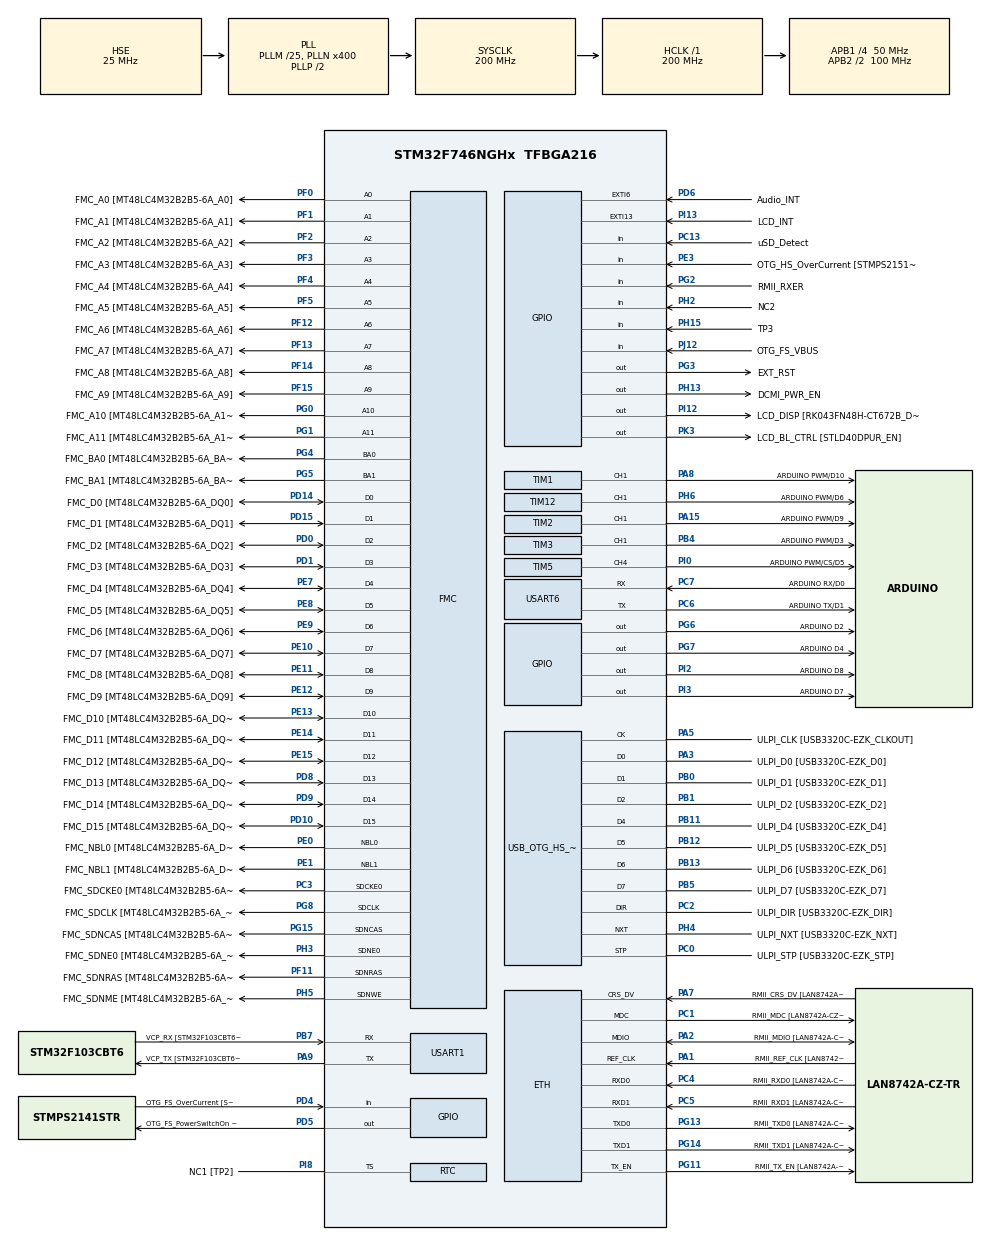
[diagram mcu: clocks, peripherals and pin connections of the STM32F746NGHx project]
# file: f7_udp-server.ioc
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VP_TIM5_VS_ClockSourceINT.Mode=Internal
PD12.GPIO_Label=QSPI_D1 [N25Q128A13EF840E_DQ1]
FMC.SDClockPeriod2=FMC_SDRAM_CLOCK_PERIOD_2
FMC.SDClockPeriod1=FMC_SDRAM_CLOCK_PERIOD_2
SH.FMC_A0.0=FMC_A0,12b-sda1
PH15.GPIO_Label=TP3
NVIC.TIM6_DAC_IRQn=true\:0\:0\:false\:false\:true\:false\:false\:true
PG8.Signal=FMC_SDCLK
PG0.Signal=FMC_A10
PI15.GPIO_Label=LCD_R0 [RK043FN48H-CT672B_R0]
PK1.Signal=LTDC_G6
SH.FMC_D5_DA5.0=FMC_D5,sd-16b-d1
PF10.GPIO_PuPd=GPIO_NOPULL
SH.FMC_D9_DA9.0=FMC_D9,sd-16b-d1
PG15.GPIO_Label=FMC_SDNCAS [MT48LC4M32B2B5-6A_CAS]
PF7.Signal=ADC3_IN5
RCC.PLL48CLockSelection=RCC_CLK48SOURCE_PLLSAIP
SH.FMC_SDNWE.0=FMC_SDNWE,12b-sda1
PH9.Signal=DCMI_D0
SH.FMC_D11_DA11.0=FMC_D11,sd-16b-d1
RCC.APB2TimFreq_Value=200000000
PB6.Signal=QUADSPI_BK1_NCS
PC7.Signal=USART6_RX
PD0.Signal=FMC_D2_DA2
PD8.Signal=FMC_D13_DA13
USART6.VirtualMode-Asynchronous=VM_ASYNC
PE1.Signal=FMC_NBL1
PF1.GPIO_Label=FMC_A1 [MT48LC4M32B2B5-6A_A1]
PI4.GPIO_Label=SAI2_MCLKA [WM8994ECS/R_MCLK1]
PK4.GPIO_Label=LCD_B5 [RK043FN48H-CT672B_B5]
PD1.GPIO_Label=FMC_D3 [MT48LC4M32B2B5-6A_DQ3]
PB12.GPIO_Label=ULPI_D5 [USB3320C-EZK_D5]
PG14.Mode=RMII
FMC.SelfRefreshTime1=4
PF12.GPIO_Label=FMC_A6 [MT48LC4M32B2B5-6A_A6]
SH.S_TIM12_CH1.0=TIM12_CH1,PWM Generation1 CH1
PC4.GPIO_Label=RMII_RXD0 [LAN8742A-CZ-TR_RXD0]
TIM1.Channel-PWM\ Generation1\ CH1=TIM_CHANNEL_1
PE9.Signal=FMC_D6_DA6
SH.FMC_A2.0=FMC_A2,12b-sda1
PB1.GPIO_Label=ULPI_D2 [USB3320C-EZK_D2]
PE4.GPIO_Label=LCD_B0 [RK043FN48H-CT672B_B0]
PG4.GPIO_Label=FMC_BA0 [MT48LC4M32B2B5-6A_BA0]
PA8.Signal=S_TIM1_CH1
ETH.PHY_Name=LAN8742A_PHY_ADDRESS
SH.FMC_D1_DA1.0=FMC_D1,sd-16b-d1
PJ14.Signal=LTDC_B2
PB9.Signal=I2C1_SDA
Mcu.Package=TFBGA216
PB1.Signal=USB_OTG_HS_ULPI_D2
PB14.GPIO_PuPd=GPIO_NOPULL
NVIC.TimeBase=TIM6_DAC_IRQn
PD12.Signal=QUADSPI_BK1_IO1
NVIC.TimeBaseIP=TIM6
PB9.GPIO_PuPd=GPIO_NOPULL
PA10.Signal=USB_OTG_FS_ID
VP_RTC_VS_RTC_Calendar.Mode=RTC_Calendar
PE12.GPIO_Label=FMC_D9 [MT48LC4M32B2B5-6A_DQ9]
FMC.WriteRecoveryTime1=3
RCC.APB2CLKDivider=RCC_HCLK_DIV2
RCC.APB1TimFreq_Value=100000000
PC14/OSC32_IN.GPIO_Label=RCC_OSC32_IN
FMC.RowCycleDelay2=7
FMC.RowCycleDelay1=7
PB13.Mode=Host_HS
PF9.GPIO_PuPd=GPIO_NOPULL
PA4.GPIO_Label=DCMI_HSYNC
PA8.GPIO_Speed=GPIO_SPEED_FREQ_LOW
PD15.Signal=FMC_D1_DA1
PJ1.GPIO_Label=LCD_R2 [RK043FN48H-CT672B_R2]
PG12.Signal=LTDC_B4
PA5.Mode=Host_HS
SH.FMC_A4.0=FMC_A4,12b-sda1
PK4.Signal=LTDC_B5
FREERTOS.Tasks01=defaultTask,24,4096,StartDefaultTask,Default,NULL,Dynamic,NULL,NULL
PH13.Signal=GPIO_Output
PI13.GPIO_ModeDefaultEXTI=GPIO_MODE_EVT_RISING
PG5.Signal=FMC_A15_BA1
PC13.Signal=GPIO_Input
SH.FMC_D10_DA10.0=FMC_D10,sd-16b-d1
PD3.Signal=DCMI_D5
PC2.Signal=USB_OTG_HS_ULPI_DIR
PI12.Signal=GPIO_Output
PJ11.Signal=LTDC_G4
RCC.PLLSAIRDiv=RCC_PLLSAIDIVR_8
PF8.GPIO_Label=ARDUINO A3
PD10.Signal=FMC_D15_DA15
PA3.Mode=Host_HS
PB8.GPIO_Label=ARDUINO SCL/D15
PJ8.GPIO_Label=LCD_G1 [RK043FN48H-CT672B_G1]
PJ3.Signal=LTDC_R4
PI8.GPIO_Label=NC1 [TP2]
PA8.GPIO_Label=ARDUINO PWM/D10
PE8.GPIO_Label=FMC_D5 [MT48LC4M32B2B5-6A_DQ5]
PH11.GPIO_Label=DCMI_D2
VP_TIM8_VS_ClockSourceINT.Mode=Internal
PJ11.GPIO_Label=LCD_G4 [RK043FN48H-CT672B_G4]
PB14.Signal=SPI2_MISO
PA5.Signal=USB_OTG_HS_ULPI_CK
PF10.GPIO_Mode=GPIO_MODE_ANALOG
PJ4.GPIO_Label=LCD_R5 [RK043FN48H-CT672B_R5]
PE1.GPIO_Label=FMC_NBL1 [MT48LC4M32B2B5-6A_DQM1]
PK7.GPIO_Label=LCD_DE [RK043FN48H-CT672B_DE]
PI7.Signal=SAI2_FS_A
FMC.ReadBurst1=FMC_SDRAM_RBURST_ENABLE
SH.FMC_A6.0=FMC_A6,12b-sda1
FMC.ReadBurst2=FMC_SDRAM_RBURST_ENABLE
PE14.Signal=FMC_D11_DA11
PB4.GPIO_Label=ARDUINO PWM/D3
PB15.GPIO_Label=ARDUINO MOSI/PWM/D11
PG7.GPIO_Label=ARDUINO D4
PI2.Signal=GPIO_Output
PF4.GPIO_Label=FMC_A4 [MT48LC4M32B2B5-6A_A4]
PA1.GPIO_Label=RMII_REF_CLK [LAN8742A-CZ-TR_REFCLK0]
PF13.Signal=FMC_A7
PA0/WKUP.GPIO_PuPd=GPIO_NOPULL
PJ15.GPIO_Label=LCD_B3 [RK043FN48H-CT672B_B3]
LWIP.CMSIS_VERSION-Enabled=1
PC7.GPIO_Label=ARDUINO RX/D0
ETH.MediaInterface=ETH_MEDIA_INTERFACE_RMII
PA5.GPIO_Label=ULPI_CLK [USB3320C-EZK_CLKOUT]
PC12.GPIO_Label=SDMMC_CK
PE5.GPIO_Label=DCMI_D6
PJ8.Signal=LTDC_G1
PJ0.GPIO_Label=LCD_R1 [RK043FN48H-CT672B_R1]
ProjectManager.HeapSize=0x200
PB1.Mode=Host_HS
PH6.Signal=S_TIM12_CH1
FREERTOS.configUSE_RECURSIVE_MUTEXES=1
NVIC.PriorityGroup=NVIC_PRIORITYGROUP_4
PF0.GPIO_Label=FMC_A0 [MT48LC4M32B2B5-6A_A0]
PI1.GPIO_Mode=GPIO_MODE_AF_PP
PE3.Signal=GPIO_Input
PC15/OSC32_OUT.Signal=RCC_OSC32_OUT
PF4.Signal=FMC_A4
PD2.Signal=SDMMC1_CMD
PI1.GPIO_Label=ARDUINO SCK/D13
PC1.Mode=RMII
Mcu.Family=STM32F7
PK3.Signal=GPIO_Output
SH.FMC_A8.0=FMC_A8,12b-sda1
PC15/OSC32_OUT.GPIO_Label=RCC_OSC32_OUT
PH14.Signal=DCMI_D4
PH10.Signal=DCMI_D1
SH.FMC_D14_DA14.0=FMC_D14,sd-16b-d1
PG2.Signal=GPIO_Input
PE11.GPIO_Label=FMC_D8 [MT48LC4M32B2B5-6A_DQ8]
PD0.GPIO_Label=FMC_D2 [MT48LC4M32B2B5-6A_DQ2]
PC14/OSC32_IN.Mode=LSE-External-Oscillator
SH.FMC_A14_BA0.0=FMC_BA0,FourSdramBanks1
SH.FMC_A11.0=FMC_A11,12b-sda1
PB13.GPIO_Label=ULPI_D6 [USB3320C-EZK_D6]
PG5.GPIO_Label=FMC_BA1 [MT48LC4M32B2B5-6A_BA1]
PB15.Signal=SPI2_MOSI
VP_RTC_VS_RTC_Alarm_B_Intern.Mode=Alarm B
PG15.Signal=FMC_SDNCAS
PG11.Signal=ETH_TX_EN
PJ5.GPIO_Label=LCD_R6 [RK043FN48H-CT672B_R6]
PJ14.GPIO_Label=LCD_B2 [RK043FN48H-CT672B_B2]
PD13.Signal=QUADSPI_BK1_IO3
PA15.GPIO_Label=ARDUINO PWM/D9
PJ2.Signal=LTDC_R3
SH.FMC_NBL1.0=FMC_NBL1,Sd2ByteEnable1
PA15.GPIO_ModeDefaultPP=GPIO_MODE_AF_PP
TIM3.Channel-PWM\ Generation1\ CH1=TIM_CHANNEL_1
PA9.GPIO_Mode=GPIO_MODE_AF_PP
RCC.HSE_VALUE=25000000
FMC.ExitSelfRefreshDelay1=7
PF7.GPIO_Mode=GPIO_MODE_ANALOG
TIM5.Channel-PWM\ Generation4\ CH4=TIM_CHANNEL_4
PF8.GPIO_PuPd=GPIO_NOPULL
PA14.Mode=Serial_Wire
PH7.GPIO_Label=LCD_SCL [RK043FN48H-CT672B_SCL]
PJ7.GPIO_Label=LCD_G0 [RK043FN48H-CT672B_G0]
PF11.Signal=FMC_SDNRAS
PB5.Mode=Host_HS
PC11.GPIO_Label=SDMMC_D3
PJ12.GPIO_Label=OTG_FS_VBUS
PB7.Signal=USART1_RX
TIM2.Channel-PWM\ Generation1\ CH1=TIM_CHANNEL_1
SH.S_TIM3_CH1.0=TIM3_CH1,PWM Generation1 CH1
ETH.PHY_RESET_DELAY=0x00000FFF
PI8.Mode=Timestamp enabled - Input Enabled to TS
PB7.GPIO_Label=VCP_RX [STM32F103CBT6_PA2]
PD13.GPIO_Label=QSPI_D3 [N25Q128A13EF840E_DQ3]
PA6.Signal=DCMI_PIXCLK
PB12.Mode=Host_HS
PB15.GPIO_PuPd=GPIO_NOPULL
PD5.GPIO_Label=OTG_FS_PowerSwitchOn [STMPS2141STR_EN]
PA15.Signal=S_TIM2_CH1_ETR
PF8.Signal=ADC3_IN6
PG0.GPIO_Label=FMC_A10 [MT48LC4M32B2B5-6A_A10]
PI0.GPIO_Label=ARDUINO PWM/CS/D5
PA0/WKUP.GPIO_Mode=GPIO_MODE_ANALOG
PB5.GPIO_Label=ULPI_D7 [USB3320C-EZK_D7]
PG11.GPIO_Label=RMII_TX_EN [LAN8742A-CZ-TR_TXEN]
PD3.GPIO_Label=DCMI_D5
PC5.Signal=ETH_RXD1
PE7.Signal=FMC_D4_DA4
PD6.Signal=GPXTI6
PF3.GPIO_Label=FMC_A3 [MT48LC4M32B2B5-6A_A3]
PE2.GPIO_Label=QSPI_D2 [N25Q128A13EF840E_DQ2]
VP_TIM3_VS_ClockSourceINT.Mode=Internal
PB4.Signal=S_TIM3_CH1
PG2.GPIO_Label=RMII_RXER
PA3.Signal=USB_OTG_HS_ULPI_D0
PK6.Signal=LTDC_B7
PD15.GPIO_Label=FMC_D1 [MT48LC4M32B2B5-6A_DQ1]
PG7.Signal=GPIO_Output
PH12.GPIO_Label=DCMI_D3
PC11.Signal=SDMMC1_D3
PI14.Signal=LTDC_CLK
PC8.Signal=SDMMC1_D0
PC2.Mode=Host_HS
PE14.GPIO_Label=FMC_D11 [MT48LC4M32B2B5-6A_DQ11]
PD9.Signal=FMC_D14_DA14
PA9.GPIO_PuPd=GPIO_NOPULL
PA12.GPIO_Label=OTG_FS_P
PD8.GPIO_Label=FMC_D13 [MT48LC4M32B2B5-6A_DQ13]
PG8.GPIO_Label=FMC_SDCLK [MT48LC4M32B2B5-6A_CLK]
USART1.VirtualMode-Asynchronous=VM_ASYNC
PA13.Signal=SYS_JTMS-SWDIO
FREERTOS.configUSE_IDLE_HOOK=1
PA9.Mode=Asynchronous
SH.S_TIM1_CH1.0=TIM1_CH1,PWM Generation1 CH1
PF6.Signal=ADC3_IN4
PB10.GPIO_Label=ULPI_D3 [USB3320C-EZK_D3]
SH.FMC_D13_DA13.0=FMC_D13,sd-16b-d1
PH8.Signal=I2C3_SDA
RCC.USBFreq_Value=48000000
PF9.GPIO_Label=ARDUINO A2
PD10.GPIO_Label=FMC_D15 [MT48LC4M32B2B5-6A_DQ15]
PA1.Signal=ETH_REF_CLK
board=STM32F746G-DISCO
RCC.VCOOutputFreq_Value=400000000
PI9.Signal=LTDC_VSYNC
PH4.GPIO_Label=ULPI_NXT [USB3320C-EZK_NXT]
TIM12.Channel-PWM\ Generation1\ CH1=TIM_CHANNEL_1
PI13.GPIO_Label=LCD_INT
PI4.Signal=SAI2_MCLK_A
PC1.GPIO_Label=RMII_MDC [LAN8742A-CZ-TR_MDC]
SH.FMC_D12_DA12.0=FMC_D12,sd-16b-d1
PF15.GPIO_Label=FMC_A9 [MT48LC4M32B2B5-6A_A9]
PI1.GPIO_Speed=GPIO_SPEED_FREQ_LOW
PF1.Signal=FMC_A1
PF8.GPIO_Mode=GPIO_MODE_ANALOG
PJ0.Signal=LTDC_R1
PE0.Signal=FMC_NBL0
RTC.Alarm-Alarm\ A=RTC_ALARM_A
PE7.GPIO_Label=FMC_D4 [MT48LC4M32B2B5-6A_DQ4]
PE12.Signal=FMC_D9_DA9
RCC.SYSCLKFreq_VALUE=200000000
PJ5.Signal=LTDC_R6
PA15.GPIO_Speed=GPIO_SPEED_FREQ_LOW
RCC.HSI_VALUE=16000000
PA8.GPIO_PuPd=GPIO_NOPULL
PH0/OSC_IN.GPIO_Label=OSC_25M [NZ2520SB-25.00M_OUT]
PF9.GPIO_Mode=GPIO_MODE_ANALOG
RCC.PLLQ=9
PI3.GPIO_Label=ARDUINO D7
PH3.Signal=FMC_SDNE0
RCC.PLLM=25
RCC.PLLN=400
PA9.GPIO_Speed=GPIO_SPEED_FREQ_LOW
PA2.Mode=RMII
PB8.GPIO_Speed=GPIO_SPEED_FREQ_LOW
PJ2.GPIO_Label=LCD_R3 [RK043FN48H-CT672B_R3]
VP_CRC_VS_CRC.Mode=CRC_Activate
PB14.GPIO_Mode=GPIO_MODE_AF_PP
RCC.PLLI2SN=100
PB12.Signal=USB_OTG_HS_ULPI_D5
PJ13.Signal=LTDC_B1
PK1.GPIO_Label=LCD_G6 [RK043FN48H-CT672B_G6]
PA3.GPIO_Label=ULPI_D0 [USB3320C-EZK_D0]
PI12.PinState=GPIO_PIN_SET
SH.FMC_D7_DA7.0=FMC_D7,sd-16b-d1
RTC.Alarm_B-Alarm\ B=RTC_ALARM_B
PK5.Signal=LTDC_B6
PB15.GPIO_Mode=GPIO_MODE_AF_PP
VP_SYS_VS_tim6.Mode=TIM6
PH12.Signal=DCMI_D3
FMC.RCDDelay1=2
PG4.Signal=FMC_A14_BA0
PC12.Signal=SDMMC1_CK
PB14.GPIO_Label=ARDUINO MISO/D12
PA14.GPIO_Label=SWCLK
PG6.GPIO_Label=ARDUINO D2
PH6.GPIO_Label=ARDUINO PWM/D6
FMC.LoadToActiveDelay1=2
PK6.GPIO_Label=LCD_B7 [RK043FN48H-CT672B_B7]
PC6.GPIO_Label=ARDUINO TX/D1
VP_RTC_VS_RTC_Activate.Mode=RTC_Enabled
PI6.GPIO_Label=SAI2_SDA [WM8994ECS/R_DACDAT1]
PB6.GPIO_Label=QSPI_NCS [N25Q128A13EF840E_S]
PJ6.GPIO_Label=LCD_R7 [RK043FN48H-CT672B_R7]
PC5.Mode=RMII
PB13.Signal=USB_OTG_HS_ULPI_D6
PD6.GPIO_Label=Audio_INT
PG13.Signal=ETH_TXD0
PE6.GPIO_Label=DCMI_D7
PF6.GPIO_Label=ARDUINO A5
RCC.SYSCLKSource=RCC_SYSCLKSOURCE_PLLCLK
PJ10.Signal=LTDC_G3
SH.FMC_A15_BA1.0=FMC_BA1,FourSdramBanks1
LWIP.NETMASK_ADDRESS=255.255.255.000
PB7.GPIO_Mode=GPIO_MODE_AF_PP
PJ13.GPIO_Label=LCD_B1 [RK043FN48H-CT672B_B1]
PI0.GPIO_PuPd=GPIO_NOPULL
PH5.Signal=FMC_SDNWE
PD4.Signal=GPIO_Input
PH1/OSC_OUT.Signal=RCC_OSC_OUT
PC3.Signal=FMC_SDCKE0
PE5.Signal=DCMI_D6
PF10.GPIO_Label=ARDUINO A1
PH10.GPIO_Label=DCMI_D1
PB2.Signal=QUADSPI_CLK
PI6.Signal=SAI2_SD_A
PI3.Signal=GPIO_Output
PE2.Signal=QUADSPI_BK1_IO2
PF3.Signal=FMC_A3
PE10.Signal=FMC_D7_DA7
VP_TIM1_VS_ClockSourceINT.Mode=Internal
RCC.SDMMCClockSelection=RCC_SDMMC1CLKSOURCE_CLK48
PD6.GPIO_ModeDefaultEXTI=GPIO_MODE_EVT_RISING
PJ4.Signal=LTDC_R5
SH.FMC_A1.0=FMC_A1,12b-sda1
PH2.Signal=GPIO_Input
SH.FMC_SDCLK.0=FMC_SDCLK,12b-sda1
PF14.Signal=FMC_A8
PF6.GPIO_Mode=GPIO_MODE_ANALOG
PE10.GPIO_Label=FMC_D7 [MT48LC4M32B2B5-6A_DQ7]
SH.FMC_D3_DA3.0=FMC_D3,sd-16b-d1
PC4.Mode=RMII
LWIP.IP_ADDRESS=192.168.000.044
PI10.GPIO_Label=LCD_HSYNC [RK043FN48H-CT672B_HSYNC]
PB7.GPIO_PuPd=GPIO_NOPULL
PK3.PinState=GPIO_PIN_SET
PH15.Signal=GPIO_Input
PD9.GPIO_Label=FMC_D14 [MT48LC4M32B2B5-6A_DQ14]
PG9.Signal=DCMI_VSYNC
PA9.GPIO_Label=VCP_TX [STM32F103CBT6_PA3]
FREERTOS.configCHECK_FOR_STACK_OVERFLOW=2
PB8.GPIO_PuPd=GPIO_NOPULL
PC6.Signal=USART6_TX
ETH.MACAddr=00\:80\:E1\:00\:00\:45
PB11.GPIO_Label=ULPI_D4 [USB3320C-EZK_D4]
PD7.Signal=SPDIFRX_IN0
PD1.Signal=FMC_D3_DA3
PA11.GPIO_Label=OTG_FS_N
PF14.GPIO_Label=FMC_A8 [MT48LC4M32B2B5-6A_A8]
LWIP.LWIP_DHCP=0
PC0.Signal=USB_OTG_HS_ULPI_STP
RCC.APB1CLKDivider=RCC_HCLK_DIV4
PF13.GPIO_Label=FMC_A7 [MT48LC4M32B2B5-6A_A7]
PG13.GPIO_Label=RMII_TXD0 [LAN8742A-CZ-TR_TXD0]
PG10.Signal=SAI2_SD_B
SH.FMC_A3.0=FMC_A3,12b-sda1
PJ7.Signal=LTDC_G0
FMC.CASLatency1=FMC_SDRAM_CAS_LATENCY_3
PB11.Mode=Host_HS
PI0.GPIO_Speed=GPIO_SPEED_FREQ_LOW
PB14.GPIO_Speed=GPIO_SPEED_FREQ_LOW
SH.FMC_D15_DA15.0=FMC_D15,sd-16b-d1
PC6.Mode=Asynchronous
PA9.Signal=USART1_TX
PB4.GPIO_PuPd=GPIO_NOPULL
PE9.GPIO_Label=FMC_D6 [MT48LC4M32B2B5-6A_DQ6]
PB10.Signal=USB_OTG_HS_ULPI_D3
PJ15.Signal=LTDC_B3
PH9.GPIO_Label=DCMI_D0
PI9.GPIO_Label=LCD_VSYNC [RK043FN48H-CT672B_VSYNC]
PA8.GPIO_ModeDefaultPP=GPIO_MODE_AF_PP
PA1.Mode=RMII
PE15.Signal=FMC_D12_DA12
PE8.Signal=FMC_D5_DA5
PI1.Signal=SPI2_SCK
PA0/WKUP.GPIO_Label=ARDUINO A0
PG14.GPIO_Label=RMII_TXD1 [LAN8742A-CZ-TR_TXD1]
PA13.Mode=Serial_Wire
SH.FMC_SDNCAS.0=FMC_SDNCAS,12b-sda1
PH4.Mode=Host_HS
PF7.GPIO_PuPd=GPIO_NOPULL
PH14.GPIO_Label=DCMI_D4
PA4.Signal=DCMI_HSYNC
PB5.Signal=USB_OTG_HS_ULPI_D7
PE13.GPIO_Label=FMC_D10 [MT48LC4M32B2B5-6A_DQ10]
FREERTOS.configUSE_COUNTING_SEMAPHORES=1
PD11.Signal=QUADSPI_BK1_IO0
SH.FMC_A5.0=FMC_A5,12b-sda1
PG11.Mode=RMII
PA11.Signal=USB_OTG_FS_DM
SH.S_TIM2_CH1_ETR.0=TIM2_CH1,PWM Generation1 CH1
PK3.GPIO_Label=LCD_BL_CTRL [STLD40DPUR_EN]
LWIP.Version=v2.1.2_Cube
PF9.Signal=ADC3_IN7
PF6.GPIO_PuPd=GPIO_NOPULL
PC3.GPIO_Label=FMC_SDCKE0 [MT48LC4M32B2B5-6A_CKE]
PG3.GPIO_Label=EXT_RST
PB0.Signal=USB_OTG_HS_ULPI_D1
PC1.Signal=ETH_MDC
PG10.GPIO_Label=SAI2_SDB [WM8994ECS/R_ADCDAT1]
PD2.GPIO_Label=SDMMC_CMD
PH2.GPIO_Label=NC2
PC3.Mode=SdramChipSelect1_1
PK7.Signal=LTDC_DE
RCC.CortexFreq_Value=200000000
PG6.Signal=GPIO_Output
PC10.Signal=SDMMC1_D2
SH.FMC_NBL0.0=FMC_NBL0,Sd2ByteEnable1
PC0.GPIO_Label=ULPI_STP [USB3320C-EZK_STP]
SH.FMC_D6_DA6.0=FMC_D6,sd-16b-d1
PA0/WKUP.Signal=ADCx_IN0
PB0.GPIO_Label=ULPI_D1 [USB3320C-EZK_D1]
PH5.GPIO_Label=FMC_SDNME [MT48LC4M32B2B5-6A_WE]
PI5.GPIO_Label=SAI2_SCKA [WM8994ECS/R_BCLK1]
PC13.GPIO_Label=uSD_Detect
PK5.GPIO_Label=LCD_B6 [RK043FN48H-CT672B_B6]
PB11.Signal=USB_OTG_HS_ULPI_D4
PI14.GPIO_Label=LCD_CLK [RK043FN48H-CT672B_CLK]
VP_RTC_VS_RTC_Alarm_A_Intern.Mode=Alarm A
ProjectManager.StackSize=0x400
VP_FREERTOS_VS_CMSIS_V2.Mode=CMSIS_V2
PH3.Mode=SdramChipSelect1_1
PJ6.Signal=LTDC_R7
SH.FMC_A7.0=FMC_A7,12b-sda1
PA12.Signal=USB_OTG_FS_DP
PH0/OSC_IN.Mode=HSE-External-Oscillator
PD11.GPIO_Label=QSPI_D0 [N25Q128A13EF840E_DQ0]
RCC.HCLKFreq_Value=200000000
PF11.GPIO_Label=FMC_SDNRAS [MT48LC4M32B2B5-6A_RAS]
PF12.Signal=FMC_A6
FREERTOS.configUSE_MALLOC_FAILED_HOOK=1
PI13.Signal=GPXTI13
SH.FMC_A10.0=FMC_A10,12b-sda1
RCC.AHBFreq_Value=200000000
NVIC.ETH_IRQn=true\:5\:0\:false\:false\:true\:true\:false\:true
SH.FMC_D8_DA8.0=FMC_D8,sd-16b-d1
FMC.RPDelay2=2
FMC.RPDelay1=2
PI8.Signal=RTC_TS
SH.FMC_D2_DA2.0=FMC_D2,sd-16b-d1
PE13.Signal=FMC_D10_DA10
PF7.GPIO_Label=ARDUINO A4
PI1.GPIO_PuPd=GPIO_NOPULL
PI5.Signal=SAI2_SCK_A
PI0.Signal=S_TIM5_CH4
PA10.GPIO_Label=OTG_FS_ID
PG13.Mode=RMII
SH.ADCx_IN0.0=ADC3_IN0
SH.FMC_SDNRAS.0=FMC_SDNRAS,12b-sda1
PE4.Signal=LTDC_B0
PH1/OSC_OUT.Mode=HSE-External-Oscillator
FREERTOS.configTOTAL_HEAP_SIZE=32768
PD7.GPIO_Label=SPDIF_RX0 [74LVC1G04SE_4]
PJ9.Signal=LTDC_G2
SH.FMC_D0_DA0.0=FMC_D0,sd-16b-d1
PJ12.Signal=GPIO_Input
PC14/OSC32_IN.Signal=RCC_OSC32_IN
PK0.GPIO_Label=LCD_G5 [RK043FN48H-CT672B_G5]
PA2.GPIO_Label=RMII_MDIO [LAN8742A-CZ-TR_MDIO]
PF5.GPIO_Label=FMC_A5 [MT48LC4M32B2B5-6A_A5]
SH.FMC_A9.0=FMC_A9,12b-sda1
PJ1.Signal=LTDC_R2
SH.FMC_D4_DA4.0=FMC_D4,sd-16b-d1
PI12.GPIO_Label=LCD_DISP [RK043FN48H-CT672B_DISP] 
PE0.GPIO_Label=FMC_NBL0 [MT48LC4M32B2B5-6A_DQM0]
RCC.PLLSAIN=384
PH3.GPIO_Label=FMC_SDNE0 [MT48LC4M32B2B5-6A_CS]
PF5.Signal=FMC_A5
RCC.PLLSAIP=RCC_PLLSAIP_DIV8
RCC.PLLSAIR=5
PH7.Signal=I2C3_SCL
PB9.GPIO_Speed=GPIO_SPEED_FREQ_LOW
PJ3.GPIO_Label=LCD_R4 [RK043FN48H-CT672B_R4]
PK2.GPIO_Label=LCD_G7 [RK043FN48H-CT672B_G7]
PF0.Signal=FMC_A0
PI2.GPIO_Label=ARDUINO D8
PC2.GPIO_Label=ULPI_DIR [USB3320C-EZK_DIR]
PB7.GPIO_Speed=GPIO_SPEED_FREQ_LOW
PB3.GPIO_Label=SWO
RCC.PLLSourceVirtual=RCC_PLLSOURCE_HSE
PK2.Signal=LTDC_G7
PA7.Mode=RMII
PB9.GPIO_Label=ARDUINO SDA/D14
PC10.GPIO_Label=SDMMC_D2
PH11.Signal=DCMI_D2
PG3.Signal=GPIO_Output
PG1.Signal=FMC_A11
PC4.Signal=ETH_RXD0
PI0.GPIO_ModeDefaultPP=GPIO_MODE_AF_PP
PI10.Signal=LTDC_HSYNC
PD5.Signal=GPIO_Output
FREERTOS.configUSE_APPLICATION_TASK_TAG=1
ETH.PhyAddress=0
VP_LWIP_VS_Enabled.Mode=Enabled
PC0.Mode=Host_HS
PH13.GPIO_Label=DCMI_PWR_EN
PH8.GPIO_Label=LCD_SDA [RK043FN48H-CT672B_SDA]
PE15.GPIO_Label=FMC_D12 [MT48LC4M32B2B5-6A_DQ12]
PH4.Signal=USB_OTG_HS_ULPI_NXT
ProjectManager.TargetToolchain=STM32CubeIDE
PJ9.GPIO_Label=LCD_G2 [RK043FN48H-CT672B_G2]
PF2.Signal=FMC_A2
PE11.Signal=FMC_D8_DA8
PK0.Signal=LTDC_G5
PG9.GPIO_Label=DCMI_VSYNC
PG14.Signal=ETH_TXD1
PB4.GPIO_ModeDefaultPP=GPIO_MODE_AF_PP
PJ10.GPIO_Label=LCD_G3 [RK043FN48H-CT672B_G3]
PB0.Mode=Host_HS
PG1.GPIO_Label=FMC_A11 [MT48LC4M32B2B5-6A_A11]
PB9.GPIO_Mode=GPIO_MODE_AF_OD
PH0/OSC_IN.Signal=RCC_OSC_IN
PB4.GPIO_Speed=GPIO_SPEED_FREQ_LOW
RCC.APB2Freq_Value=100000000
VP_TIM2_VS_ClockSourceINT.Mode=Internal
PD4.GPIO_Label=OTG_FS_OverCurrent [STMPS2141STR_Fault]
PF10.Signal=ADC3_IN8
PB15.GPIO_Speed=GPIO_SPEED_FREQ_LOW
PI7.GPIO_Label=SAI2_FSA [WM8994ECS/R_LRCLK1]
SH.S_TIM5_CH4.0=TIM5_CH4,PWM Generation4 CH4
PF15.Signal=FMC_A9
PD14.GPIO_Label=FMC_D0 [MT48LC4M32B2B5-6A_DQ0]
PD5.PinState=GPIO_PIN_SET
PE6.Signal=DCMI_D7
Mcu.Name=STM32F746NGHx
PA13.GPIO_Label=SWDIO
PA2.Signal=ETH_MDIO
PD14.Signal=FMC_D0_DA0
PB3.Signal=SYS_JTDO-SWO
PA7.GPIO_Label=RMII_CRS_DV [LAN8742A-CZ-TR_CRS_DV]
PC5.GPIO_Label=RMII_RXD1 [LAN8742A-CZ-TR_RXD1]
PC15/OSC32_OUT.Mode=LSE-External-Oscillator
PB7.Mode=Asynchronous
PA14.Signal=SYS_JTCK-SWCLK
PG12.GPIO_Label=LCD_B4 [RK043FN48H-CT672B_B4]
PK3.GPIO_Speed=GPIO_SPEED_FREQ_LOW
PA15.GPIO_PuPd=GPIO_NOPULL
PI15.Signal=LTDC_R0
PB8.Signal=I2C1_SCL
PE3.GPIO_Label=OTG_HS_OverCurrent [STMPS2151STR_FAULT]
PC9.Signal=SDMMC1_D1
PC7.Mode=Asynchronous
PB8.GPIO_Mode=GPIO_MODE_AF_OD
RCC.APB1Freq_Value=50000000
PA7.Signal=ETH_CRS_DV
PF2.GPIO_Label=FMC_A2 [MT48LC4M32B2B5-6A_A2]

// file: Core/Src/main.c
/* USER CODE BEGIN Header */
/**
  ******************************************************************************
  * @file           : main.c
  * @brief          : Main program body
  ******************************************************************************
  * @attention
  *
  * <h2><center>&copy; Copyright (c) 2021 STMicroelectronics.
  * All rights reserved.</center></h2>
  *
  * This software component is licensed by ST under Ultimate Liberty license
  * SLA0044, the "License"; You may not use this file except in compliance with
  * the License. You may obtain a copy of the License at:
  *                             www.st.com/SLA0044
  *
  ******************************************************************************
  */
/* USER CODE END Header */
#include "main.h"
#include "cmsis_os.h"
#include "lwip.h"

/* USER CODE BEGIN Includes */
#include "lwip/inet.h"
#include "lwip/sockets.h"
/* USER CODE END Includes */

CRC_HandleTypeDef hcrc;

RTC_HandleTypeDef hrtc;

TIM_HandleTypeDef htim1;
TIM_HandleTypeDef htim2;
TIM_HandleTypeDef htim3;
TIM_HandleTypeDef htim5;
TIM_HandleTypeDef htim8;
TIM_HandleTypeDef htim12;

UART_HandleTypeDef huart1;
UART_HandleTypeDef huart6;

SDRAM_HandleTypeDef hsdram1;

/* Definitions for defaultTask */
osThreadId_t defaultTaskHandle;
const osThreadAttr_t defaultTask_attributes = {
  .name = "defaultTask",
  .stack_size = 4096 * 4,
  .priority = (osPriority_t) osPriorityNormal,
};

void SystemClock_Config(void);
static void MX_GPIO_Init(void);
static void MX_CRC_Init(void);
static void MX_FMC_Init(void);
static void MX_RTC_Init(void);
static void MX_TIM1_Init(void);
static void MX_TIM2_Init(void);
static void MX_TIM3_Init(void);
static void MX_TIM5_Init(void);
static void MX_TIM8_Init(void);
static void MX_TIM12_Init(void);
static void MX_USART1_UART_Init(void);
static void MX_USART6_UART_Init(void);
void StartDefaultTask(void *argument);

int main(void)
{

  /* MCU Configuration--------------------------------------------------------*/

  /* Reset of all peripherals, Initializes the Flash interface and the Systick. */
  HAL_Init();

  /* Configure the system clock */
  SystemClock_Config();

  /* Initialize all configured peripherals */
  MX_GPIO_Init();
  MX_CRC_Init();
  MX_FMC_Init();
  MX_RTC_Init();
  MX_TIM1_Init();
  MX_TIM2_Init();
  MX_TIM3_Init();
  MX_TIM5_Init();
  MX_TIM8_Init();
  MX_TIM12_Init();
  MX_USART1_UART_Init();
  MX_USART6_UART_Init();

  /* Init scheduler */
  osKernelInitialize();

  /* Create the thread(s) */
  /* creation of defaultTask */
  defaultTaskHandle = osThreadNew(StartDefaultTask, NULL, &defaultTask_attributes);

  /* Start scheduler */
  osKernelStart();

  /* We should never get here as control is now taken by the scheduler */
  /* Infinite loop */
  while (1)
  {

  }
}

void SystemClock_Config(void)
{
  RCC_OscInitTypeDef RCC_OscInitStruct = {0};
  RCC_ClkInitTypeDef RCC_ClkInitStruct = {0};
  RCC_PeriphCLKInitTypeDef PeriphClkInitStruct = {0};

  /** Configure LSE Drive Capability
  */
  HAL_PWR_EnableBkUpAccess();
  /** Configure the main internal regulator output voltage
  */
  __HAL_RCC_PWR_CLK_ENABLE();
  __HAL_PWR_VOLTAGESCALING_CONFIG(PWR_REGULATOR_VOLTAGE_SCALE1);
  /** Initializes the RCC Oscillators according to the specified parameters
  * in the RCC_OscInitTypeDef structure.
  */
  RCC_OscInitStruct.OscillatorType = RCC_OSCILLATORTYPE_LSI|RCC_OSCILLATORTYPE_HSE;
  RCC_OscInitStruct.HSEState = RCC_HSE_ON;
  RCC_OscInitStruct.LSIState = RCC_LSI_ON;
  RCC_OscInitStruct.PLL.PLLState = RCC_PLL_ON;
  RCC_OscInitStruct.PLL.PLLSource = RCC_PLLSOURCE_HSE;
  RCC_OscInitStruct.PLL.PLLM = 25;
  RCC_OscInitStruct.PLL.PLLN = 400;
  RCC_OscInitStruct.PLL.PLLP = RCC_PLLP_DIV2;
  RCC_OscInitStruct.PLL.PLLQ = 9;
  if (HAL_RCC_OscConfig(&RCC_OscInitStruct) != HAL_OK)
  {
    Error_Handler();
  }
  /** Activate the Over-Drive mode
  */
  if (HAL_PWREx_EnableOverDrive() != HAL_OK)
  {
    Error_Handler();
  }
  /** Initializes the CPU, AHB and APB buses clocks
  */
  RCC_ClkInitStruct.ClockType = RCC_CLOCKTYPE_HCLK|RCC_CLOCKTYPE_SYSCLK
                              |RCC_CLOCKTYPE_PCLK1|RCC_CLOCKTYPE_PCLK2;
  RCC_ClkInitStruct.SYSCLKSource = RCC_SYSCLKSOURCE_PLLCLK;
  RCC_ClkInitStruct.AHBCLKDivider = RCC_SYSCLK_DIV1;
  RCC_ClkInitStruct.APB1CLKDivider = RCC_HCLK_DIV4;
  RCC_ClkInitStruct.APB2CLKDivider = RCC_HCLK_DIV2;

  if (HAL_RCC_ClockConfig(&RCC_ClkInitStruct, FLASH_LATENCY_6) != HAL_OK)
  {
    Error_Handler();
  }
  PeriphClkInitStruct.PeriphClockSelection = RCC_PERIPHCLK_RTC|RCC_PERIPHCLK_USART1
                              |RCC_PERIPHCLK_USART6;
  PeriphClkInitStruct.RTCClockSelection = RCC_RTCCLKSOURCE_LSI;
  PeriphClkInitStruct.Usart1ClockSelection = RCC_USART1CLKSOURCE_PCLK2;
  PeriphClkInitStruct.Usart6ClockSelection = RCC_USART6CLKSOURCE_PCLK2;
  if (HAL_RCCEx_PeriphCLKConfig(&PeriphClkInitStruct) != HAL_OK)
  {
    Error_Handler();
  }
}

static void MX_CRC_Init(void)
{

  hcrc.Instance = CRC;
  hcrc.Init.DefaultPolynomialUse = DEFAULT_POLYNOMIAL_ENABLE;
  hcrc.Init.DefaultInitValueUse = DEFAULT_INIT_VALUE_ENABLE;
  hcrc.Init.InputDataInversionMode = CRC_INPUTDATA_INVERSION_NONE;
  hcrc.Init.OutputDataInversionMode = CRC_OUTPUTDATA_INVERSION_DISABLE;
  hcrc.InputDataFormat = CRC_INPUTDATA_FORMAT_BYTES;
  if (HAL_CRC_Init(&hcrc) != HAL_OK)
  {
    Error_Handler();
  }

}

static void MX_RTC_Init(void)
{

  RTC_TimeTypeDef sTime = {0};
  RTC_DateTypeDef sDate = {0};
  RTC_AlarmTypeDef sAlarm = {0};

  /** Initialize RTC Only
  */
  hrtc.Instance = RTC;
  hrtc.Init.HourFormat = RTC_HOURFORMAT_24;
  hrtc.Init.AsynchPrediv = 127;
  hrtc.Init.SynchPrediv = 255;
  hrtc.Init.OutPut = RTC_OUTPUT_DISABLE;
  hrtc.Init.OutPutPolarity = RTC_OUTPUT_POLARITY_HIGH;
  hrtc.Init.OutPutType = RTC_OUTPUT_TYPE_OPENDRAIN;
  if (HAL_RTC_Init(&hrtc) != HAL_OK)
  {
    Error_Handler();
  }

  /** Initialize RTC and set the Time and Date
  */
  sTime.Hours = 0x0;
  sTime.Minutes = 0x0;
  sTime.Seconds = 0x0;
  sTime.DayLightSaving = RTC_DAYLIGHTSAVING_NONE;
  sTime.StoreOperation = RTC_STOREOPERATION_RESET;
  if (HAL_RTC_SetTime(&hrtc, &sTime, RTC_FORMAT_BCD) != HAL_OK)
  {
    Error_Handler();
  }
  sDate.WeekDay = RTC_WEEKDAY_MONDAY;
  sDate.Month = RTC_MONTH_JANUARY;
  sDate.Date = 0x1;
  sDate.Year = 0x0;
  if (HAL_RTC_SetDate(&hrtc, &sDate, RTC_FORMAT_BCD) != HAL_OK)
  {
    Error_Handler();
  }
  /** Enable the Alarm A
  */
  sAlarm.AlarmTime.Hours = 0x0;
  sAlarm.AlarmTime.Minutes = 0x0;
  sAlarm.AlarmTime.Seconds = 0x0;
  sAlarm.AlarmTime.SubSeconds = 0x0;
  sAlarm.AlarmTime.DayLightSaving = RTC_DAYLIGHTSAVING_NONE;
  sAlarm.AlarmTime.StoreOperation = RTC_STOREOPERATION_RESET;
  sAlarm.AlarmMask = RTC_ALARMMASK_NONE;
  sAlarm.AlarmSubSecondMask = RTC_ALARMSUBSECONDMASK_ALL;
  sAlarm.AlarmDateWeekDaySel = RTC_ALARMDATEWEEKDAYSEL_DATE;
  sAlarm.AlarmDateWeekDay = 0x1;
  sAlarm.Alarm = RTC_ALARM_A;
  if (HAL_RTC_SetAlarm(&hrtc, &sAlarm, RTC_FORMAT_BCD) != HAL_OK)
  {
    Error_Handler();
  }
  /** Enable the Alarm B
  */
  sAlarm.Alarm = RTC_ALARM_B;
  if (HAL_RTC_SetAlarm(&hrtc, &sAlarm, RTC_FORMAT_BCD) != HAL_OK)
  {
    Error_Handler();
  }
  /** Enable the TimeStamp
  */
  if (HAL_RTCEx_SetTimeStamp(&hrtc, RTC_TIMESTAMPEDGE_RISING, RTC_TIMESTAMPPIN_POS1) != HAL_OK)
  {
    Error_Handler();
  }

}

static void MX_TIM1_Init(void)
{

  TIM_ClockConfigTypeDef sClockSourceConfig = {0};
  TIM_MasterConfigTypeDef sMasterConfig = {0};
  TIM_OC_InitTypeDef sConfigOC = {0};
  TIM_BreakDeadTimeConfigTypeDef sBreakDeadTimeConfig = {0};

  htim1.Instance = TIM1;
  htim1.Init.Prescaler = 0;
  htim1.Init.CounterMode = TIM_COUNTERMODE_UP;
  htim1.Init.Period = 65535;
  htim1.Init.ClockDivision = TIM_CLOCKDIVISION_DIV1;
  htim1.Init.RepetitionCounter = 0;
  htim1.Init.AutoReloadPreload = TIM_AUTORELOAD_PRELOAD_DISABLE;
  if (HAL_TIM_Base_Init(&htim1) != HAL_OK)
  {
    Error_Handler();
  }
  sClockSourceConfig.ClockSource = TIM_CLOCKSOURCE_INTERNAL;
  if (HAL_TIM_ConfigClockSource(&htim1, &sClockSourceConfig) != HAL_OK)
  {
    Error_Handler();
  }
  if (HAL_TIM_PWM_Init(&htim1) != HAL_OK)
  {
    Error_Handler();
  }
  sMasterConfig.MasterOutputTrigger = TIM_TRGO_RESET;
  sMasterConfig.MasterOutputTrigger2 = TIM_TRGO2_RESET;
  sMasterConfig.MasterSlaveMode = TIM_MASTERSLAVEMODE_DISABLE;
  if (HAL_TIMEx_MasterConfigSynchronization(&htim1, &sMasterConfig) != HAL_OK)
  {
    Error_Handler();
  }
  sConfigOC.OCMode = TIM_OCMODE_PWM1;
  sConfigOC.Pulse = 0;
  sConfigOC.OCPolarity = TIM_OCPOLARITY_HIGH;
  sConfigOC.OCNPolarity = TIM_OCNPOLARITY_HIGH;
  sConfigOC.OCFastMode = TIM_OCFAST_DISABLE;
  sConfigOC.OCIdleState = TIM_OCIDLESTATE_RESET;
  sConfigOC.OCNIdleState = TIM_OCNIDLESTATE_RESET;
  if (HAL_TIM_PWM_ConfigChannel(&htim1, &sConfigOC, TIM_CHANNEL_1) != HAL_OK)
  {
    Error_Handler();
  }
  sBreakDeadTimeConfig.OffStateRunMode = TIM_OSSR_DISABLE;
  sBreakDeadTimeConfig.OffStateIDLEMode = TIM_OSSI_DISABLE;
  sBreakDeadTimeConfig.LockLevel = TIM_LOCKLEVEL_OFF;
  sBreakDeadTimeConfig.DeadTime = 0;
  sBreakDeadTimeConfig.BreakState = TIM_BREAK_DISABLE;
  sBreakDeadTimeConfig.BreakPolarity = TIM_BREAKPOLARITY_HIGH;
  sBreakDeadTimeConfig.BreakFilter = 0;
  sBreakDeadTimeConfig.Break2State = TIM_BREAK2_DISABLE;
  sBreakDeadTimeConfig.Break2Polarity = TIM_BREAK2POLARITY_HIGH;
  sBreakDeadTimeConfig.Break2Filter = 0;
  sBreakDeadTimeConfig.AutomaticOutput = TIM_AUTOMATICOUTPUT_DISABLE;
  if (HAL_TIMEx_ConfigBreakDeadTime(&htim1, &sBreakDeadTimeConfig) != HAL_OK)
  {
    Error_Handler();
  }
  HAL_TIM_MspPostInit(&htim1);

}

static void MX_TIM2_Init(void)
{

  TIM_ClockConfigTypeDef sClockSourceConfig = {0};
  TIM_MasterConfigTypeDef sMasterConfig = {0};
  TIM_OC_InitTypeDef sConfigOC = {0};

  htim2.Instance = TIM2;
  htim2.Init.Prescaler = 0;
  htim2.Init.CounterMode = TIM_COUNTERMODE_UP;
  htim2.Init.Period = 4294967295;
  htim2.Init.ClockDivision = TIM_CLOCKDIVISION_DIV1;
  htim2.Init.AutoReloadPreload = TIM_AUTORELOAD_PRELOAD_DISABLE;
  if (HAL_TIM_Base_Init(&htim2) != HAL_OK)
  {
    Error_Handler();
  }
  sClockSourceConfig.ClockSource = TIM_CLOCKSOURCE_INTERNAL;
  if (HAL_TIM_ConfigClockSource(&htim2, &sClockSourceConfig) != HAL_OK)
  {
    Error_Handler();
  }
  if (HAL_TIM_PWM_Init(&htim2) != HAL_OK)
  {
    Error_Handler();
  }
  sMasterConfig.MasterOutputTrigger = TIM_TRGO_RESET;
  sMasterConfig.MasterSlaveMode = TIM_MASTERSLAVEMODE_DISABLE;
  if (HAL_TIMEx_MasterConfigSynchronization(&htim2, &sMasterConfig) != HAL_OK)
  {
    Error_Handler();
  }
  sConfigOC.OCMode = TIM_OCMODE_PWM1;
  sConfigOC.Pulse = 0;
  sConfigOC.OCPolarity = TIM_OCPOLARITY_HIGH;
  sConfigOC.OCFastMode = TIM_OCFAST_DISABLE;
  if (HAL_TIM_PWM_ConfigChannel(&htim2, &sConfigOC, TIM_CHANNEL_1) != HAL_OK)
  {
    Error_Handler();
  }
  HAL_TIM_MspPostInit(&htim2);

}

static void MX_TIM3_Init(void)
{

  TIM_ClockConfigTypeDef sClockSourceConfig = {0};
  TIM_MasterConfigTypeDef sMasterConfig = {0};
  TIM_OC_InitTypeDef sConfigOC = {0};

  htim3.Instance = TIM3;
  htim3.Init.Prescaler = 0;
  htim3.Init.CounterMode = TIM_COUNTERMODE_UP;
  htim3.Init.Period = 65535;
  htim3.Init.ClockDivision = TIM_CLOCKDIVISION_DIV1;
  htim3.Init.AutoReloadPreload = TIM_AUTORELOAD_PRELOAD_DISABLE;
  if (HAL_TIM_Base_Init(&htim3) != HAL_OK)
  {
    Error_Handler();
  }
  sClockSourceConfig.ClockSource = TIM_CLOCKSOURCE_INTERNAL;
  if (HAL_TIM_ConfigClockSource(&htim3, &sClockSourceConfig) != HAL_OK)
  {
    Error_Handler();
  }
  if (HAL_TIM_PWM_Init(&htim3) != HAL_OK)
  {
    Error_Handler();
  }
  sMasterConfig.MasterOutputTrigger = TIM_TRGO_RESET;
  sMasterConfig.MasterSlaveMode = TIM_MASTERSLAVEMODE_DISABLE;
  if (HAL_TIMEx_MasterConfigSynchronization(&htim3, &sMasterConfig) != HAL_OK)
  {
    Error_Handler();
  }
  sConfigOC.OCMode = TIM_OCMODE_PWM1;
  sConfigOC.Pulse = 0;
  sConfigOC.OCPolarity = TIM_OCPOLARITY_HIGH;
  sConfigOC.OCFastMode = TIM_OCFAST_DISABLE;
  if (HAL_TIM_PWM_ConfigChannel(&htim3, &sConfigOC, TIM_CHANNEL_1) != HAL_OK)
  {
    Error_Handler();
  }
  HAL_TIM_MspPostInit(&htim3);

}

static void MX_TIM5_Init(void)
{

  TIM_ClockConfigTypeDef sClockSourceConfig = {0};
  TIM_MasterConfigTypeDef sMasterConfig = {0};
  TIM_OC_InitTypeDef sConfigOC = {0};

  htim5.Instance = TIM5;
  htim5.Init.Prescaler = 0;
  htim5.Init.CounterMode = TIM_COUNTERMODE_UP;
  htim5.Init.Period = 4294967295;
  htim5.Init.ClockDivision = TIM_CLOCKDIVISION_DIV1;
  htim5.Init.AutoReloadPreload = TIM_AUTORELOAD_PRELOAD_DISABLE;
  if (HAL_TIM_Base_Init(&htim5) != HAL_OK)
  {
    Error_Handler();
  }
  sClockSourceConfig.ClockSource = TIM_CLOCKSOURCE_INTERNAL;
  if (HAL_TIM_ConfigClockSource(&htim5, &sClockSourceConfig) != HAL_OK)
  {
    Error_Handler();
  }
  if (HAL_TIM_PWM_Init(&htim5) != HAL_OK)
  {
    Error_Handler();
  }
  sMasterConfig.MasterOutputTrigger = TIM_TRGO_RESET;
  sMasterConfig.MasterSlaveMode = TIM_MASTERSLAVEMODE_DISABLE;
  if (HAL_TIMEx_MasterConfigSynchronization(&htim5, &sMasterConfig) != HAL_OK)
  {
    Error_Handler();
  }
  sConfigOC.OCMode = TIM_OCMODE_PWM1;
  sConfigOC.Pulse = 0;
  sConfigOC.OCPolarity = TIM_OCPOLARITY_HIGH;
  sConfigOC.OCFastMode = TIM_OCFAST_DISABLE;
  if (HAL_TIM_PWM_ConfigChannel(&htim5, &sConfigOC, TIM_CHANNEL_4) != HAL_OK)
  {
    Error_Handler();
  }
  HAL_TIM_MspPostInit(&htim5);

}

static void MX_TIM8_Init(void)
{

  TIM_ClockConfigTypeDef sClockSourceConfig = {0};
  TIM_MasterConfigTypeDef sMasterConfig = {0};

  htim8.Instance = TIM8;
  htim8.Init.Prescaler = 0;
  htim8.Init.CounterMode = TIM_COUNTERMODE_UP;
  htim8.Init.Period = 65535;
  htim8.Init.ClockDivision = TIM_CLOCKDIVISION_DIV1;
  htim8.Init.RepetitionCounter = 0;
  htim8.Init.AutoReloadPreload = TIM_AUTORELOAD_PRELOAD_DISABLE;
  if (HAL_TIM_Base_Init(&htim8) != HAL_OK)
  {
    Error_Handler();
  }
  sClockSourceConfig.ClockSource = TIM_CLOCKSOURCE_INTERNAL;
  if (HAL_TIM_ConfigClockSource(&htim8, &sClockSourceConfig) != HAL_OK)
  {
    Error_Handler();
  }
  sMasterConfig.MasterOutputTrigger = TIM_TRGO_RESET;
  sMasterConfig.MasterOutputTrigger2 = TIM_TRGO2_RESET;
  sMasterConfig.MasterSlaveMode = TIM_MASTERSLAVEMODE_DISABLE;
  if (HAL_TIMEx_MasterConfigSynchronization(&htim8, &sMasterConfig) != HAL_OK)
  {
    Error_Handler();
  }

}

static void MX_TIM12_Init(void)
{

  TIM_OC_InitTypeDef sConfigOC = {0};

  htim12.Instance = TIM12;
  htim12.Init.Prescaler = 0;
  htim12.Init.CounterMode = TIM_COUNTERMODE_UP;
  htim12.Init.Period = 65535;
  htim12.Init.ClockDivision = TIM_CLOCKDIVISION_DIV1;
  htim12.Init.AutoReloadPreload = TIM_AUTORELOAD_PRELOAD_DISABLE;
  if (HAL_TIM_PWM_Init(&htim12) != HAL_OK)
  {
    Error_Handler();
  }
  sConfigOC.OCMode = TIM_OCMODE_PWM1;
  sConfigOC.Pulse = 0;
  sConfigOC.OCPolarity = TIM_OCPOLARITY_HIGH;
  sConfigOC.OCFastMode = TIM_OCFAST_DISABLE;
  if (HAL_TIM_PWM_ConfigChannel(&htim12, &sConfigOC, TIM_CHANNEL_1) != HAL_OK)
  {
    Error_Handler();
  }
  HAL_TIM_MspPostInit(&htim12);

}

static void MX_USART1_UART_Init(void)
{

  huart1.Instance = USART1;
  huart1.Init.BaudRate = 115200;
  huart1.Init.WordLength = UART_WORDLENGTH_8B;
  huart1.Init.StopBits = UART_STOPBITS_1;
  huart1.Init.Parity = UART_PARITY_NONE;
  huart1.Init.Mode = UART_MODE_TX_RX;
  huart1.Init.HwFlowCtl = UART_HWCONTROL_NONE;
  huart1.Init.OverSampling = UART_OVERSAMPLING_16;
  huart1.Init.OneBitSampling = UART_ONE_BIT_SAMPLE_DISABLE;
  huart1.AdvancedInit.AdvFeatureInit = UART_ADVFEATURE_NO_INIT;
  if (HAL_UART_Init(&huart1) != HAL_OK)
  {
    Error_Handler();
  }

}

static void MX_USART6_UART_Init(void)
{

  huart6.Instance = USART6;
  huart6.Init.BaudRate = 115200;
  huart6.Init.WordLength = UART_WORDLENGTH_8B;
  huart6.Init.StopBits = UART_STOPBITS_1;
  huart6.Init.Parity = UART_PARITY_NONE;
  huart6.Init.Mode = UART_MODE_TX_RX;
  huart6.Init.HwFlowCtl = UART_HWCONTROL_NONE;
  huart6.Init.OverSampling = UART_OVERSAMPLING_16;
  huart6.Init.OneBitSampling = UART_ONE_BIT_SAMPLE_DISABLE;
  huart6.AdvancedInit.AdvFeatureInit = UART_ADVFEATURE_NO_INIT;
  if (HAL_UART_Init(&huart6) != HAL_OK)
  {
    Error_Handler();
  }

}

/* FMC initialization function */
static void MX_FMC_Init(void)
{

  FMC_SDRAM_TimingTypeDef SdramTiming = {0};

  /** Perform the SDRAM1 memory initialization sequence
  */
  hsdram1.Instance = FMC_SDRAM_DEVICE;
  /* hsdram1.Init */
  hsdram1.Init.SDBank = FMC_SDRAM_BANK1;
  hsdram1.Init.ColumnBitsNumber = FMC_SDRAM_COLUMN_BITS_NUM_8;
  hsdram1.Init.RowBitsNumber = FMC_SDRAM_ROW_BITS_NUM_12;
  hsdram1.Init.MemoryDataWidth = FMC_SDRAM_MEM_BUS_WIDTH_16;
  hsdram1.Init.InternalBankNumber = FMC_SDRAM_INTERN_BANKS_NUM_4;
  hsdram1.Init.CASLatency = FMC_SDRAM_CAS_LATENCY_3;
  hsdram1.Init.WriteProtection = FMC_SDRAM_WRITE_PROTECTION_DISABLE;
  hsdram1.Init.SDClockPeriod = FMC_SDRAM_CLOCK_PERIOD_2;
  hsdram1.Init.ReadBurst = FMC_SDRAM_RBURST_ENABLE;
  hsdram1.Init.ReadPipeDelay = FMC_SDRAM_RPIPE_DELAY_0;
  /* SdramTiming */
  SdramTiming.LoadToActiveDelay = 2;
  SdramTiming.ExitSelfRefreshDelay = 7;
  SdramTiming.SelfRefreshTime = 4;
  SdramTiming.RowCycleDelay = 7;
  SdramTiming.WriteRecoveryTime = 3;
  SdramTiming.RPDelay = 2;
  SdramTiming.RCDDelay = 2;

  if (HAL_SDRAM_Init(&hsdram1, &SdramTiming) != HAL_OK)
  {
    Error_Handler( );
  }

}

static void MX_GPIO_Init(void)
{
  GPIO_InitTypeDef GPIO_InitStruct = {0};

  /* GPIO Ports Clock Enable */
  __HAL_RCC_GPIOE_CLK_ENABLE();
  __HAL_RCC_GPIOG_CLK_ENABLE();
  __HAL_RCC_GPIOB_CLK_ENABLE();
  __HAL_RCC_GPIOD_CLK_ENABLE();
  __HAL_RCC_GPIOC_CLK_ENABLE();
  __HAL_RCC_GPIOA_CLK_ENABLE();
  __HAL_RCC_GPIOJ_CLK_ENABLE();
  __HAL_RCC_GPIOI_CLK_ENABLE();
  __HAL_RCC_GPIOK_CLK_ENABLE();
  __HAL_RCC_GPIOF_CLK_ENABLE();
  __HAL_RCC_GPIOH_CLK_ENABLE();

  /*Configure GPIO pin Output Level */
  HAL_GPIO_WritePin(OTG_FS_PowerSwitchOn_GPIO_Port, OTG_FS_PowerSwitchOn_Pin, GPIO_PIN_SET);

  /*Configure GPIO pin Output Level */
  HAL_GPIO_WritePin(GPIOI, ARDUINO_D7_Pin|ARDUINO_D8_Pin, GPIO_PIN_RESET);

  /*Configure GPIO pin Output Level */
  HAL_GPIO_WritePin(LCD_BL_CTRL_GPIO_Port, LCD_BL_CTRL_Pin, GPIO_PIN_SET);

  /*Configure GPIO pin Output Level */
  HAL_GPIO_WritePin(LCD_DISP_GPIO_Port, LCD_DISP_Pin, GPIO_PIN_SET);

  /*Configure GPIO pin Output Level */
  HAL_GPIO_WritePin(DCMI_PWR_EN_GPIO_Port, DCMI_PWR_EN_Pin, GPIO_PIN_RESET);

  /*Configure GPIO pin Output Level */
  HAL_GPIO_WritePin(GPIOG, ARDUINO_D4_Pin|ARDUINO_D2_Pin|EXT_RST_Pin, GPIO_PIN_RESET);

  /*Configure GPIO pin : LCD_B0_Pin */
  GPIO_InitStruct.Pin = LCD_B0_Pin;
  GPIO_InitStruct.Mode = GPIO_MODE_AF_PP;
  GPIO_InitStruct.Pull = GPIO_NOPULL;
  GPIO_InitStruct.Speed = GPIO_SPEED_FREQ_LOW;
  GPIO_InitStruct.Alternate = GPIO_AF14_LTDC;
  HAL_GPIO_Init(LCD_B0_GPIO_Port, &GPIO_InitStruct);

  /*Configure GPIO pin : OTG_HS_OverCurrent_Pin */
  GPIO_InitStruct.Pin = OTG_HS_OverCurrent_Pin;
  GPIO_InitStruct.Mode = GPIO_MODE_INPUT;
  GPIO_InitStruct.Pull = GPIO_NOPULL;
  HAL_GPIO_Init(OTG_HS_OverCurrent_GPIO_Port, &GPIO_InitStruct);

  /*Configure GPIO pin : QSPI_D2_Pin */
  GPIO_InitStruct.Pin = QSPI_D2_Pin;
  GPIO_InitStruct.Mode = GPIO_MODE_AF_PP;
  GPIO_InitStruct.Pull = GPIO_NOPULL;
  GPIO_InitStruct.Speed = GPIO_SPEED_FREQ_VERY_HIGH;
  GPIO_InitStruct.Alternate = GPIO_AF9_QUADSPI;
  HAL_GPIO_Init(QSPI_D2_GPIO_Port, &GPIO_InitStruct);

  /*Configure GPIO pins : ARDUINO_SCL_D15_Pin ARDUINO_SDA_D14_Pin */
  GPIO_InitStruct.Pin = ARDUINO_SCL_D15_Pin|ARDUINO_SDA_D14_Pin;
  GPIO_InitStruct.Mode = GPIO_MODE_AF_OD;
  GPIO_InitStruct.Pull = GPIO_PULLUP;
  GPIO_InitStruct.Speed = GPIO_SPEED_FREQ_LOW;
  GPIO_InitStruct.Alternate = GPIO_AF4_I2C1;
  HAL_GPIO_Init(GPIOB, &GPIO_InitStruct);

  /*Configure GPIO pins : ULPI_D7_Pin ULPI_D6_Pin ULPI_D5_Pin ULPI_D3_Pin
                           ULPI_D2_Pin ULPI_D1_Pin ULPI_D4_Pin */
  GPIO_InitStruct.Pin = ULPI_D7_Pin|ULPI_D6_Pin|ULPI_D5_Pin|ULPI_D3_Pin
                          |ULPI_D2_Pin|ULPI_D1_Pin|ULPI_D4_Pin;
  GPIO_InitStruct.Mode = GPIO_MODE_AF_PP;
  GPIO_InitStruct.Pull = GPIO_NOPULL;
  GPIO_InitStruct.Speed = GPIO_SPEED_FREQ_VERY_HIGH;
  GPIO_InitStruct.Alternate = GPIO_AF10_OTG_HS;
  HAL_GPIO_Init(GPIOB, &GPIO_InitStruct);

  /*Configure GPIO pin : SPDIF_RX0_Pin */
  GPIO_InitStruct.Pin = SPDIF_RX0_Pin;
  GPIO_InitStruct.Mode = GPIO_MODE_AF_PP;
  GPIO_InitStruct.Pull = GPIO_NOPULL;
  GPIO_InitStruct.Speed = GPIO_SPEED_FREQ_LOW;
  GPIO_InitStruct.Alternate = GPIO_AF8_SPDIFRX;
  HAL_GPIO_Init(SPDIF_RX0_GPIO_Port, &GPIO_InitStruct);

  /*Configure GPIO pins : SDMMC_CK_Pin SDMMC_D3_Pin SDMMC_D2_Pin PC9
                           PC8 */
  GPIO_InitStruct.Pin = SDMMC_CK_Pin|SDMMC_D3_Pin|SDMMC_D2_Pin|GPIO_PIN_9
                          |GPIO_PIN_8;
  GPIO_InitStruct.Mode = GPIO_MODE_AF_PP;
  GPIO_InitStruct.Pull = GPIO_NOPULL;
  GPIO_InitStruct.Speed = GPIO_SPEED_FREQ_VERY_HIGH;
  GPIO_InitStruct.Alternate = GPIO_AF12_SDMMC1;
  HAL_GPIO_Init(GPIOC, &GPIO_InitStruct);

  /*Configure GPIO pins : DCMI_D6_Pin DCMI_D7_Pin */
  GPIO_InitStruct.Pin = DCMI_D6_Pin|DCMI_D7_Pin;
  GPIO_InitStruct.Mode = GPIO_MODE_AF_PP;
  GPIO_InitStruct.Pull = GPIO_NOPULL;
  GPIO_InitStruct.Speed = GPIO_SPEED_FREQ_LOW;
  GPIO_InitStruct.Alternate = GPIO_AF13_DCMI;
  HAL_GPIO_Init(GPIOE, &GPIO_InitStruct);

  /*Configure GPIO pin : QSPI_NCS_Pin */
  GPIO_InitStruct.Pin = QSPI_NCS_Pin;
  GPIO_InitStruct.Mode = GPIO_MODE_AF_PP;
  GPIO_InitStruct.Pull = GPIO_NOPULL;
  GPIO_InitStruct.Speed = GPIO_SPEED_FREQ_VERY_HIGH;
  GPIO_InitStruct.Alternate = GPIO_AF10_QUADSPI;
  HAL_GPIO_Init(QSPI_NCS_GPIO_Port, &GPIO_InitStruct);

  /*Configure GPIO pins : LCD_B1_Pin LCD_B2_Pin LCD_B3_Pin LCD_G4_Pin
                           LCD_G1_Pin LCD_G3_Pin LCD_G0_Pin LCD_G2_Pin
                           LCD_R7_Pin LCD_R5_Pin LCD_R6_Pin LCD_R4_Pin
                           LCD_R3_Pin LCD_R1_Pin LCD_R2_Pin */
  GPIO_InitStruct.Pin = LCD_B1_Pin|LCD_B2_Pin|LCD_B3_Pin|LCD_G4_Pin
                          |LCD_G1_Pin|LCD_G3_Pin|LCD_G0_Pin|LCD_G2_Pin
                          |LCD_R7_Pin|LCD_R5_Pin|LCD_R6_Pin|LCD_R4_Pin
                          |LCD_R3_Pin|LCD_R1_Pin|LCD_R2_Pin;
  GPIO_InitStruct.Mode = GPIO_MODE_AF_PP;
  GPIO_InitStruct.Pull = GPIO_NOPULL;
  GPIO_InitStruct.Speed = GPIO_SPEED_FREQ_LOW;
  GPIO_InitStruct.Alternate = GPIO_AF14_LTDC;
  HAL_GPIO_Init(GPIOJ, &GPIO_InitStruct);

  /*Configure GPIO pin : OTG_FS_VBUS_Pin */
  GPIO_InitStruct.Pin = OTG_FS_VBUS_Pin;
  GPIO_InitStruct.Mode = GPIO_MODE_INPUT;
  GPIO_InitStruct.Pull = GPIO_NOPULL;
  HAL_GPIO_Init(OTG_FS_VBUS_GPIO_Port, &GPIO_InitStruct);

  /*Configure GPIO pin : Audio_INT_Pin */
  GPIO_InitStruct.Pin = Audio_INT_Pin;
  GPIO_InitStruct.Mode = GPIO_MODE_EVT_RISING;
  GPIO_InitStruct.Pull = GPIO_NOPULL;
  HAL_GPIO_Init(Audio_INT_GPIO_Port, &GPIO_InitStruct);

  /*Configure GPIO pins : OTG_FS_P_Pin OTG_FS_N_Pin OTG_FS_ID_Pin */
  GPIO_InitStruct.Pin = OTG_FS_P_Pin|OTG_FS_N_Pin|OTG_FS_ID_Pin;
  GPIO_InitStruct.Mode = GPIO_MODE_AF_PP;
  GPIO_InitStruct.Pull = GPIO_NOPULL;
  GPIO_InitStruct.Speed = GPIO_SPEED_FREQ_VERY_HIGH;
  GPIO_InitStruct.Alternate = GPIO_AF10_OTG_FS;
  HAL_GPIO_Init(GPIOA, &GPIO_InitStruct);

  /*Configure GPIO pins : SAI2_MCLKA_Pin SAI2_SCKA_Pin SAI2_FSA_Pin SAI2_SDA_Pin */
  GPIO_InitStruct.Pin = SAI2_MCLKA_Pin|SAI2_SCKA_Pin|SAI2_FSA_Pin|SAI2_SDA_Pin;
  GPIO_InitStruct.Mode = GPIO_MODE_AF_PP;
  GPIO_InitStruct.Pull = GPIO_NOPULL;
  GPIO_InitStruct.Speed = GPIO_SPEED_FREQ_LOW;
  GPIO_InitStruct.Alternate = GPIO_AF10_SAI2;
  HAL_GPIO_Init(GPIOI, &GPIO_InitStruct);

  /*Configure GPIO pins : LCD_DE_Pin LCD_B7_Pin LCD_B6_Pin LCD_B5_Pin
                           LCD_G6_Pin LCD_G7_Pin LCD_G5_Pin */
  GPIO_InitStruct.Pin = LCD_DE_Pin|LCD_B7_Pin|LCD_B6_Pin|LCD_B5_Pin
                          |LCD_G6_Pin|LCD_G7_Pin|LCD_G5_Pin;
  GPIO_InitStruct.Mode = GPIO_MODE_AF_PP;
  GPIO_InitStruct.Pull = GPIO_NOPULL;
  GPIO_InitStruct.Speed = GPIO_SPEED_FREQ_LOW;
  GPIO_InitStruct.Alternate = GPIO_AF14_LTDC;
  HAL_GPIO_Init(GPIOK, &GPIO_InitStruct);

  /*Configure GPIO pin : LCD_B4_Pin */
  GPIO_InitStruct.Pin = LCD_B4_Pin;
  GPIO_InitStruct.Mode = GPIO_MODE_AF_PP;
  GPIO_InitStruct.Pull = GPIO_NOPULL;
  GPIO_InitStruct.Speed = GPIO_SPEED_FREQ_LOW;
  GPIO_InitStruct.Alternate = GPIO_AF9_LTDC;
  HAL_GPIO_Init(LCD_B4_GPIO_Port, &GPIO_InitStruct);

  /*Configure GPIO pin : SAI2_SDB_Pin */
  GPIO_InitStruct.Pin = SAI2_SDB_Pin;
  GPIO_InitStruct.Mode = GPIO_MODE_AF_PP;
  GPIO_InitStruct.Pull = GPIO_NOPULL;
  GPIO_InitStruct.Speed = GPIO_SPEED_FREQ_LOW;
  GPIO_InitStruct.Alternate = GPIO_AF10_SAI2;
  HAL_GPIO_Init(SAI2_SDB_GPIO_Port, &GPIO_InitStruct);

  /*Configure GPIO pin : OTG_FS_PowerSwitchOn_Pin */
  GPIO_InitStruct.Pin = OTG_FS_PowerSwitchOn_Pin;
  GPIO_InitStruct.Mode = GPIO_MODE_OUTPUT_PP;
  GPIO_InitStruct.Pull = GPIO_NOPULL;
  GPIO_InitStruct.Speed = GPIO_SPEED_FREQ_LOW;
  HAL_GPIO_Init(OTG_FS_PowerSwitchOn_GPIO_Port, &GPIO_InitStruct);

  /*Configure GPIO pin : DCMI_D5_Pin */
  GPIO_InitStruct.Pin = DCMI_D5_Pin;
  GPIO_InitStruct.Mode = GPIO_MODE_AF_PP;
  GPIO_InitStruct.Pull = GPIO_NOPULL;
  GPIO_InitStruct.Speed = GPIO_SPEED_FREQ_LOW;
  GPIO_InitStruct.Alternate = GPIO_AF13_DCMI;
  HAL_GPIO_Init(DCMI_D5_GPIO_Port, &GPIO_InitStruct);

  /*Configure GPIO pins : ARDUINO_D7_Pin ARDUINO_D8_Pin LCD_DISP_Pin */
  GPIO_InitStruct.Pin = ARDUINO_D7_Pin|ARDUINO_D8_Pin|LCD_DISP_Pin;
  GPIO_InitStruct.Mode = GPIO_MODE_OUTPUT_PP;
  GPIO_InitStruct.Pull = GPIO_NOPULL;
  GPIO_InitStruct.Speed = GPIO_SPEED_FREQ_LOW;
  HAL_GPIO_Init(GPIOI, &GPIO_InitStruct);

  /*Configure GPIO pin : uSD_Detect_Pin */
  GPIO_InitStruct.Pin = uSD_Detect_Pin;
  GPIO_InitStruct.Mode = GPIO_MODE_INPUT;
  GPIO_InitStruct.Pull = GPIO_NOPULL;
  HAL_GPIO_Init(uSD_Detect_GPIO_Port, &GPIO_InitStruct);

  /*Configure GPIO pins : LCD_HSYNC_Pin LCD_VSYNC_Pin LCD_R0_Pin LCD_CLK_Pin */
  GPIO_InitStruct.Pin = LCD_HSYNC_Pin|LCD_VSYNC_Pin|LCD_R0_Pin|LCD_CLK_Pin;
  GPIO_InitStruct.Mode = GPIO_MODE_AF_PP;
  GPIO_InitStruct.Pull = GPIO_NOPULL;
  GPIO_InitStruct.Speed = GPIO_SPEED_FREQ_LOW;
  GPIO_InitStruct.Alternate = GPIO_AF14_LTDC;
  HAL_GPIO_Init(GPIOI, &GPIO_InitStruct);

  /*Configure GPIO pin : LCD_BL_CTRL_Pin */
  GPIO_InitStruct.Pin = LCD_BL_CTRL_Pin;
  GPIO_InitStruct.Mode = GPIO_MODE_OUTPUT_PP;
  GPIO_InitStruct.Pull = GPIO_NOPULL;
  GPIO_InitStruct.Speed = GPIO_SPEED_FREQ_LOW;
  HAL_GPIO_Init(LCD_BL_CTRL_GPIO_Port, &GPIO_InitStruct);

  /*Configure GPIO pin : DCMI_VSYNC_Pin */
  GPIO_InitStruct.Pin = DCMI_VSYNC_Pin;
  GPIO_InitStruct.Mode = GPIO_MODE_AF_PP;
  GPIO_InitStruct.Pull = GPIO_NOPULL;
  GPIO_InitStruct.Speed = GPIO_SPEED_FREQ_LOW;
  GPIO_InitStruct.Alternate = GPIO_AF13_DCMI;
  HAL_GPIO_Init(DCMI_VSYNC_GPIO_Port, &GPIO_InitStruct);

  /*Configure GPIO pin : OTG_FS_OverCurrent_Pin */
  GPIO_InitStruct.Pin = OTG_FS_OverCurrent_Pin;
  GPIO_InitStruct.Mode = GPIO_MODE_INPUT;
  GPIO_InitStruct.Pull = GPIO_NOPULL;
  HAL_GPIO_Init(OTG_FS_OverCurrent_GPIO_Port, &GPIO_InitStruct);

  /*Configure GPIO pin : SDMMC_CMD_Pin */
  GPIO_InitStruct.Pin = SDMMC_CMD_Pin;
  GPIO_InitStruct.Mode = GPIO_MODE_AF_PP;
  GPIO_InitStruct.Pull = GPIO_NOPULL;
  GPIO_InitStruct.Speed = GPIO_SPEED_FREQ_VERY_HIGH;
  GPIO_InitStruct.Alternate = GPIO_AF12_SDMMC1;
  HAL_GPIO_Init(SDMMC_CMD_GPIO_Port, &GPIO_InitStruct);

  /*Configure GPIO pins : TP3_Pin NC2_Pin */
  GPIO_InitStruct.Pin = TP3_Pin|NC2_Pin;
  GPIO_InitStruct.Mode = GPIO_MODE_INPUT;
  GPIO_InitStruct.Pull = GPIO_NOPULL;
  HAL_GPIO_Init(GPIOH, &GPIO_InitStruct);

  /*Configure GPIO pin : ARDUINO_SCK_D13_Pin */
  GPIO_InitStruct.Pin = ARDUINO_SCK_D13_Pin;
  GPIO_InitStruct.Mode = GPIO_MODE_AF_PP;
  GPIO_InitStruct.Pull = GPIO_NOPULL;
  GPIO_InitStruct.Speed = GPIO_SPEED_FREQ_LOW;
  GPIO_InitStruct.Alternate = GPIO_AF5_SPI2;
  HAL_GPIO_Init(ARDUINO_SCK_D13_GPIO_Port, &GPIO_InitStruct);

  /*Configure GPIO pin : DCMI_PWR_EN_Pin */
  GPIO_InitStruct.Pin = DCMI_PWR_EN_Pin;
  GPIO_InitStruct.Mode = GPIO_MODE_OUTPUT_PP;
  GPIO_InitStruct.Pull = GPIO_NOPULL;
  GPIO_InitStruct.Speed = GPIO_SPEED_FREQ_LOW;
  HAL_GPIO_Init(DCMI_PWR_EN_GPIO_Port, &GPIO_InitStruct);

  /*Configure GPIO pins : DCMI_D4_Pin DCMI_D3_Pin DCMI_D0_Pin DCMI_D2_Pin
                           DCMI_D1_Pin */
  GPIO_InitStruct.Pin = DCMI_D4_Pin|DCMI_D3_Pin|DCMI_D0_Pin|DCMI_D2_Pin
                          |DCMI_D1_Pin;
  GPIO_InitStruct.Mode = GPIO_MODE_AF_PP;
  GPIO_InitStruct.Pull = GPIO_NOPULL;
  GPIO_InitStruct.Speed = GPIO_SPEED_FREQ_LOW;
  GPIO_InitStruct.Alternate = GPIO_AF13_DCMI;
  HAL_GPIO_Init(GPIOH, &GPIO_InitStruct);

  /*Configure GPIO pin : LCD_INT_Pin */
  GPIO_InitStruct.Pin = LCD_INT_Pin;
  GPIO_InitStruct.Mode = GPIO_MODE_EVT_RISING;
  GPIO_InitStruct.Pull = GPIO_NOPULL;
  HAL_GPIO_Init(LCD_INT_GPIO_Port, &GPIO_InitStruct);

  /*Configure GPIO pin : ULPI_NXT_Pin */
  GPIO_InitStruct.Pin = ULPI_NXT_Pin;
  GPIO_InitStruct.Mode = GPIO_MODE_AF_PP;
  GPIO_InitStruct.Pull = GPIO_NOPULL;
  GPIO_InitStruct.Speed = GPIO_SPEED_FREQ_VERY_HIGH;
  GPIO_InitStruct.Alternate = GPIO_AF10_OTG_HS;
  HAL_GPIO_Init(ULPI_NXT_GPIO_Port, &GPIO_InitStruct);

  /*Configure GPIO pins : ARDUINO_D4_Pin ARDUINO_D2_Pin EXT_RST_Pin */
  GPIO_InitStruct.Pin = ARDUINO_D4_Pin|ARDUINO_D2_Pin|EXT_RST_Pin;
  GPIO_InitStruct.Mode = GPIO_MODE_OUTPUT_PP;
  GPIO_InitStruct.Pull = GPIO_NOPULL;
  GPIO_InitStruct.Speed = GPIO_SPEED_FREQ_LOW;
  HAL_GPIO_Init(GPIOG, &GPIO_InitStruct);

  /*Configure GPIO pins : ARDUINO_A4_Pin ARDUINO_A5_Pin ARDUINO_A1_Pin ARDUINO_A2_Pin
                           ARDUINO_A3_Pin */
  GPIO_InitStruct.Pin = ARDUINO_A4_Pin|ARDUINO_A5_Pin|ARDUINO_A1_Pin|ARDUINO_A2_Pin
                          |ARDUINO_A3_Pin;
  GPIO_InitStruct.Mode = GPIO_MODE_ANALOG;
  GPIO_InitStruct.Pull = GPIO_NOPULL;
  HAL_GPIO_Init(GPIOF, &GPIO_InitStruct);

  /*Configure GPIO pins : ULPI_STP_Pin ULPI_DIR_Pin */
  GPIO_InitStruct.Pin = ULPI_STP_Pin|ULPI_DIR_Pin;
  GPIO_InitStruct.Mode = GPIO_MODE_AF_PP;
  GPIO_InitStruct.Pull = GPIO_NOPULL;
  GPIO_InitStruct.Speed = GPIO_SPEED_FREQ_VERY_HIGH;
  GPIO_InitStruct.Alternate = GPIO_AF10_OTG_HS;
  HAL_GPIO_Init(GPIOC, &GPIO_InitStruct);

  /*Configure GPIO pin : PB2 */
  GPIO_InitStruct.Pin = GPIO_PIN_2;
  GPIO_InitStruct.Mode = GPIO_MODE_AF_PP;
  GPIO_InitStruct.Pull = GPIO_NOPULL;
  GPIO_InitStruct.Speed = GPIO_SPEED_FREQ_VERY_HIGH;
  GPIO_InitStruct.Alternate = GPIO_AF9_QUADSPI;
  HAL_GPIO_Init(GPIOB, &GPIO_InitStruct);

  /*Configure GPIO pins : QSPI_D1_Pin QSPI_D3_Pin QSPI_D0_Pin */
  GPIO_InitStruct.Pin = QSPI_D1_Pin|QSPI_D3_Pin|QSPI_D0_Pin;
  GPIO_InitStruct.Mode = GPIO_MODE_AF_PP;
  GPIO_InitStruct.Pull = GPIO_NOPULL;
  GPIO_InitStruct.Speed = GPIO_SPEED_FREQ_VERY_HIGH;
  GPIO_InitStruct.Alternate = GPIO_AF9_QUADSPI;
  HAL_GPIO_Init(GPIOD, &GPIO_InitStruct);

  /*Configure GPIO pin : RMII_RXER_Pin */
  GPIO_InitStruct.Pin = RMII_RXER_Pin;
  GPIO_InitStruct.Mode = GPIO_MODE_INPUT;
  GPIO_InitStruct.Pull = GPIO_NOPULL;
  HAL_GPIO_Init(RMII_RXER_GPIO_Port, &GPIO_InitStruct);

  /*Configure GPIO pin : ARDUINO_A0_Pin */
  GPIO_InitStruct.Pin = ARDUINO_A0_Pin;
  GPIO_InitStruct.Mode = GPIO_MODE_ANALOG;
  GPIO_InitStruct.Pull = GPIO_NOPULL;
  HAL_GPIO_Init(ARDUINO_A0_GPIO_Port, &GPIO_InitStruct);

  /*Configure GPIO pins : DCMI_HSYNC_Pin PA6 */
  GPIO_InitStruct.Pin = DCMI_HSYNC_Pin|GPIO_PIN_6;
  GPIO_InitStruct.Mode = GPIO_MODE_AF_PP;
  GPIO_InitStruct.Pull = GPIO_NOPULL;
  GPIO_InitStruct.Speed = GPIO_SPEED_FREQ_LOW;
  GPIO_InitStruct.Alternate = GPIO_AF13_DCMI;
  HAL_GPIO_Init(GPIOA, &GPIO_InitStruct);

  /*Configure GPIO pins : LCD_SCL_Pin LCD_SDA_Pin */
  GPIO_InitStruct.Pin = LCD_SCL_Pin|LCD_SDA_Pin;
  GPIO_InitStruct.Mode = GPIO_MODE_AF_OD;
  GPIO_InitStruct.Pull = GPIO_PULLUP;
  GPIO_InitStruct.Speed = GPIO_SPEED_FREQ_VERY_HIGH;
  GPIO_InitStruct.Alternate = GPIO_AF4_I2C3;
  HAL_GPIO_Init(GPIOH, &GPIO_InitStruct);

  /*Configure GPIO pins : ULPI_CLK_Pin ULPI_D0_Pin */
  GPIO_InitStruct.Pin = ULPI_CLK_Pin|ULPI_D0_Pin;
  GPIO_InitStruct.Mode = GPIO_MODE_AF_PP;
  GPIO_InitStruct.Pull = GPIO_NOPULL;
  GPIO_InitStruct.Speed = GPIO_SPEED_FREQ_VERY_HIGH;
  GPIO_InitStruct.Alternate = GPIO_AF10_OTG_HS;
  HAL_GPIO_Init(GPIOA, &GPIO_InitStruct);

  /*Configure GPIO pins : ARDUINO_MISO_D12_Pin ARDUINO_MOSI_PWM_D11_Pin */
  GPIO_InitStruct.Pin = ARDUINO_MISO_D12_Pin|ARDUINO_MOSI_PWM_D11_Pin;
  GPIO_InitStruct.Mode = GPIO_MODE_AF_PP;
  GPIO_InitStruct.Pull = GPIO_NOPULL;
  GPIO_InitStruct.Speed = GPIO_SPEED_FREQ_LOW;
  GPIO_InitStruct.Alternate = GPIO_AF5_SPI2;
  HAL_GPIO_Init(GPIOB, &GPIO_InitStruct);

}

void StartDefaultTask(void *argument)
{
  /* init code for LWIP */
  MX_LWIP_Init();
  /* USER CODE BEGIN 5 */

  void reverse(char s[])
  {
      int length = strlen(s) ;
      int c, i, j;

      for (i = 0, j = length - 1; i < j; i++, j--)
      {
          c = s[i];
          s[i] = s[j];
          s[j] = c;
      }
  }

  const unsigned SERVER_PORT = 5000;
  struct sockaddr_in server_address;

  memset(&server_address, 0, sizeof(server_address));
  server_address.sin_family = AF_INET;
  server_address.sin_port = htons(SERVER_PORT);
  server_address.sin_addr.s_addr = htonl(INADDR_ANY);

  int sock;
  if ((sock = socket(PF_INET, SOCK_DGRAM, 0)) < 0) {
    printf("could not create socket\n");
    return;
  }

  if ((bind(sock, (struct sockaddr *)&server_address,
	    sizeof(server_address))) < 0) {
    printf("could not bind socket\n");
    return;
  }

  struct sockaddr_in client_address;
  socklen_t client_address_len = 0;

  char buffer[500];
  char * ptr;

  printf("start loop \n\r");
  /* Infinite loop */
  for(;;)
  {
    client_address_len = sizeof(client_address);
    int len = recvfrom(sock, buffer, sizeof(buffer), 0,
		 (struct sockaddr *)&client_address,
		 &client_address_len);
    buffer[len] = '\0';

    // Get the first line
    ptr = strchr(buffer, '\n');
    if (ptr) *ptr = '\0';

    // Reverse the string
    reverse(buffer);

    // Append new line
    strcat(buffer, "\n");
    len = strlen(buffer);

    printf("\n\r received: '%s' %d from client %s\n", buffer, len,
    	       inet_ntoa(client_address.sin_addr));
    // Echo back
    sendto(sock, buffer, len, 0, (struct sockaddr *)&client_address,
	       sizeof(client_address));

    osDelay(1);
  }
  /* USER CODE END 5 */
}

 /**
  * @brief  Period elapsed callback in non blocking mode
  * @note   This function is called  when TIM6 interrupt took place, inside
  * HAL_TIM_IRQHandler(). It makes a direct call to HAL_IncTick() to increment
  * a global variable "uwTick" used as application time base.
  * @param  htim : TIM handle
  * @retval None
  */
void HAL_TIM_PeriodElapsedCallback(TIM_HandleTypeDef *htim)
{
  if (htim->Instance == TIM6) {
    HAL_IncTick();
  }
}

void Error_Handler(void)
{
  __disable_irq();
  while (1)
  {
  }
}

/************************ (C) COPYRIGHT STMicroelectronics *****END OF FILE****/
